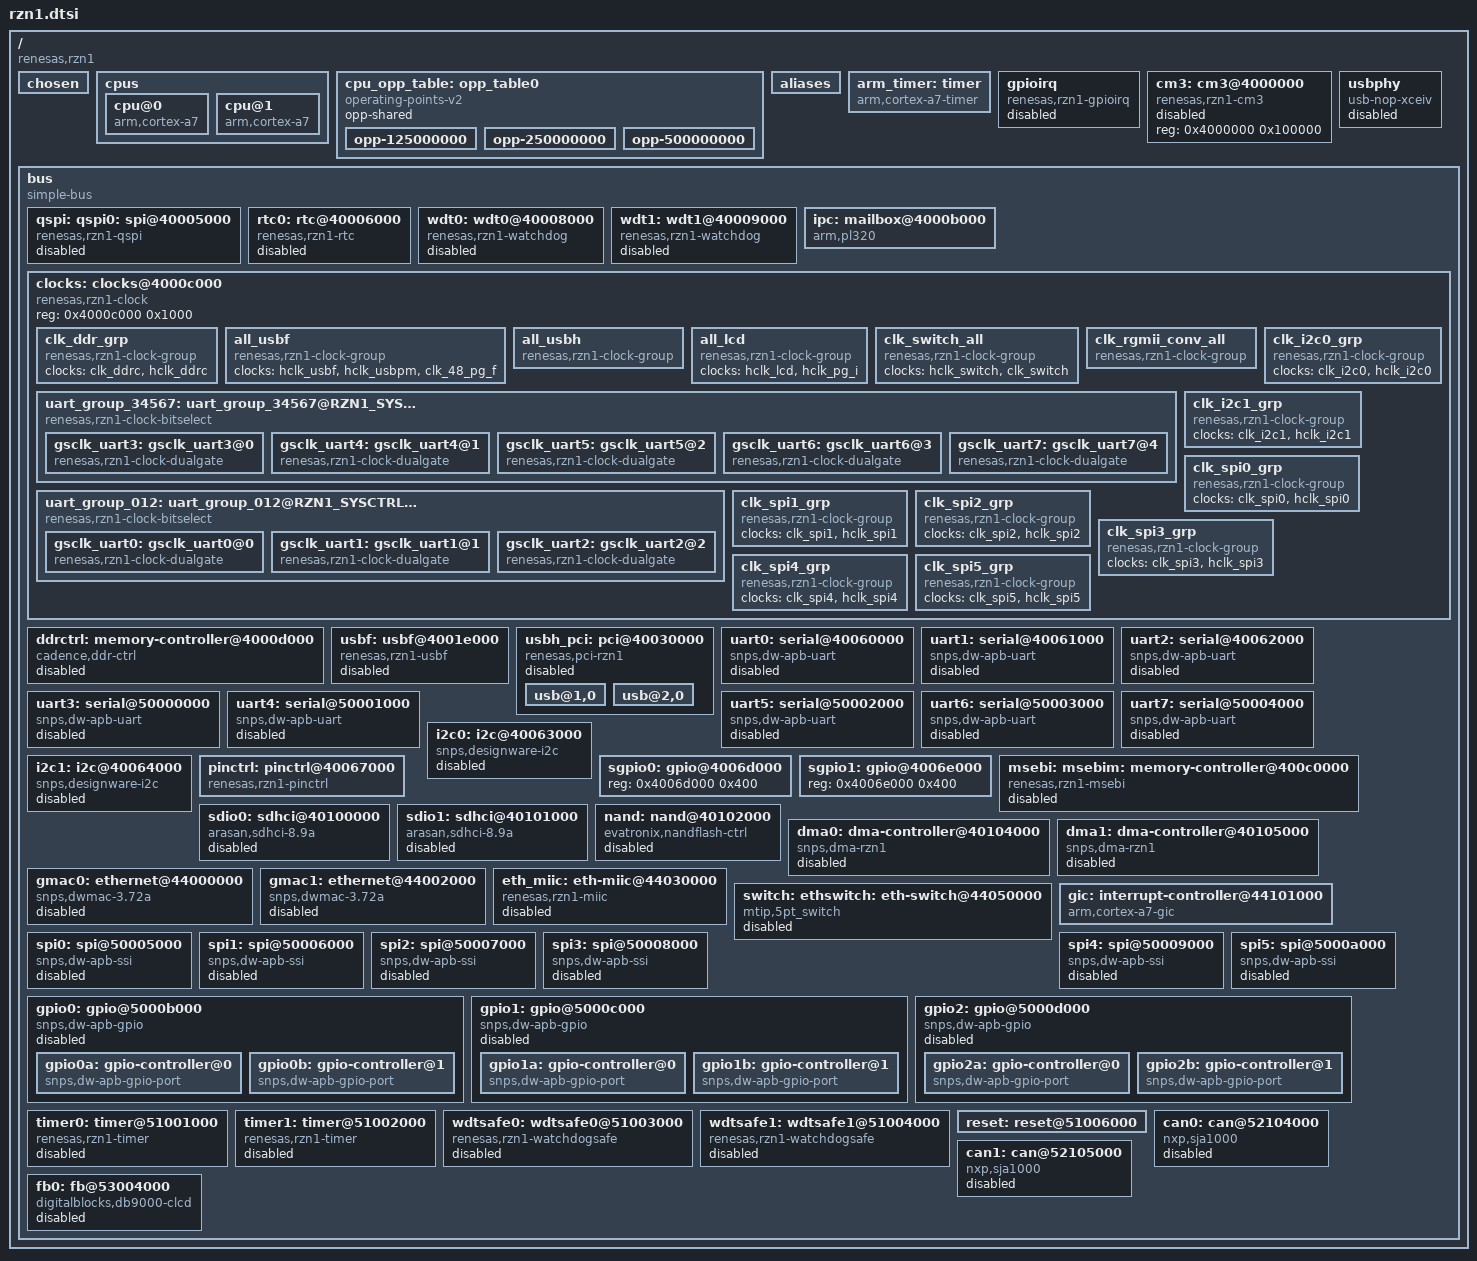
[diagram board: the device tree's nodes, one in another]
/*
 * Device Tree Source for the Renesas RZ/N1 SoC
 *
 * Copyright (C) 2016 Renesas Electronics Europe Ltd
 *
 * This file is licensed under the terms of the GNU General Public License
 * version 2.  This program is licensed "as is" without any warranty of any
 * kind, whether express or implied.
 */

#include <dt-bindings/interrupt-controller/arm-gic.h>
#include <dt-bindings/gpio/gpio.h>
#include <dt-bindings/interrupt-controller/rzn1-irq.h>
#include <dt-bindings/soc/rzn1-memory-map.h>
#include <dt-bindings/soc/rzn1-sysctrl.h>
#include <dt-bindings/pinctrl/pinctrl-rzn1.h>
#include <dt-bindings/clock/rzn1-clocks.h>

#include "skeleton.dtsi"

/ {
	compatible = "renesas,rzn1";
	#address-cells = <1>;
	#size-cells = <1>;

	chosen {
		/* These nodes are specific to the rzn1, and are CAN by the
		 * bootloader. They are optional
		   rzn1,bootaddr = <0xxxxxxxxx>  -- this property is set
		        by the bootloader when it starts in NONSEC mode, this
		        property will contain the address that the second CA7
		        core is 'parked' at, and where it is looking for the
		        boot address code the kernel will pass to it to start it.
		        This property should not be set manually.
		   rzn1,h2mode   -- this bool property, if present, will force
		        the kernel to configure the USB subsystem in 'host' mode,
		        this mode will prevent the usbf 'device' driver to start.
		        This property can be set by the bootloader in case there
		        is a GPIO for this configutation, otherwise, it can also
		        be set manually in the device tree to force a config.
		 */
	};
	cpus {
		#address-cells = <1>;
		#size-cells = <0>;

		cpu@0 {
			device_type = "cpu";
			compatible = "arm,cortex-a7";
			reg = <0>;
			clocks = <&clk_a7mp>;
			operating-points-v2 = <&cpu_opp_table>;
		};
		cpu@1 {
			device_type = "cpu";
			compatible = "arm,cortex-a7";
			reg = <1>;
			clocks = <&clk_a7mp>;
			operating-points-v2 = <&cpu_opp_table>;
		};
	};

	cpu_opp_table: opp_table0 {
		compatible = "operating-points-v2";
		opp-shared;

		opp-125000000 {
			opp-hz = /bits/ 64 <125000000>;
			/* ~35 clocks cycles at 125mhz */
			clock-latency-ns = <300>;
		};
		opp-250000000 {
			opp-hz = /bits/ 64 <250000000>;
			clock-latency-ns = <300>;
		};
		opp-500000000 {
			opp-hz = /bits/ 64 <500000000>;
			clock-latency-ns = <300>;
		};
	};

	aliases {
		serial0 = &uart0;
		ethernet0 = &gmac0;
		ethernet1 = &gmac1;
		spi0 = &qspi0;
		i2c0 = &i2c0;
		i2c1 = &i2c1;
	};

	arm_timer: timer {
		compatible = "arm,cortex-a7-timer",
			     "arm,armv7-timer";
		interrupt-parent = <&gic>;
		arm,cpu-registers-not-fw-configured;
		always-on;
		interrupts =
			<GIC_PPI 13 (GIC_CPU_MASK_SIMPLE(2) | IRQ_TYPE_LEVEL_LOW)>,
			<GIC_PPI 14 (GIC_CPU_MASK_SIMPLE(2) | IRQ_TYPE_LEVEL_LOW)>,
			<GIC_PPI 11 (GIC_CPU_MASK_SIMPLE(2) | IRQ_TYPE_LEVEL_LOW)>,
			<GIC_PPI 10 (GIC_CPU_MASK_SIMPLE(2) | IRQ_TYPE_LEVEL_LOW)>;
	};

	gpioirq: gpioirq {
		compatible = "renesas,rzn1-gpioirq";
		status = "disabled";
		interrupt-parent = <&gic>;
		interrupts =
			<GIC_SPI 103 IRQ_TYPE_LEVEL_HIGH>,
			<GIC_SPI 104 IRQ_TYPE_LEVEL_HIGH>,
			<GIC_SPI 105 IRQ_TYPE_LEVEL_HIGH>,
			<GIC_SPI 106 IRQ_TYPE_LEVEL_HIGH>,
			<GIC_SPI 107 IRQ_TYPE_LEVEL_HIGH>,
			<GIC_SPI 108 IRQ_TYPE_LEVEL_HIGH>,
			<GIC_SPI 109 IRQ_TYPE_LEVEL_HIGH>,
			<GIC_SPI 110 IRQ_TYPE_LEVEL_HIGH>;
		interrupt-controller;
		#interrupt-cells = <1>;
	};

	cm3: cm3@4000000 {
		compatible = "renesas,rzn1-cm3";
		#address-cells = <1>;
		#size-cells = <0>;
		status = "disabled";
		reg = <0x4000000 0x100000>;
		/* Optional, load and run a CM3 firmware at boot time */
		/* firmware-name = "cm3-freertos.bin"; */
	};

	usbphy: usbphy {
		#phy-cells = <0>;
		compatible = "usb-nop-xceiv";
		status = "disabled";
	};

	bus {
		compatible = "simple-bus";
		#address-cells = <1>;
		#size-cells = <1>;
		interrupt-parent = <&gic>;
		ranges;
		u-boot,dm-pre-reloc;

		qspi: qspi0: spi@40005000 {
			compatible = "renesas,rzn1-qspi";
			#address-cells = <1>;
			#size-cells = <0>;
			reg = <0x40005000 0x1000
				0x10000000 0x10000000>;
			reg-names = "qspi", "qspi-mapping";
			interrupts = <GIC_SPI 64 IRQ_TYPE_LEVEL_HIGH>;
			clocks = <&hclk_qspi0>, <&clk_qspi0>;
			clock-names = "flexway", "pclk";
			status = "disabled";
		};

		rtc0: rtc@40006000 {
			#address-cells = <1>;
			compatible = "renesas,rzn1-rtc";
			reg = <0x40006000 0x1000>;
			clock-names = "axi";
			clocks = <&hclk_rtc>;
			interrupt-names = "alarm", "intr", "1hz";
			interrupts =
				<GIC_SPI 66 IRQ_TYPE_EDGE_RISING>,
				<GIC_SPI 67 IRQ_TYPE_EDGE_RISING>,
				<GIC_SPI 68 IRQ_TYPE_EDGE_RISING>;
			status = "disabled";
		};

		wdt0: wdt0@40008000 {
			compatible = "renesas,rzn1-watchdog";
			reg = <0x40008000 0x1000>;
			interrupts = <GIC_SPI 73 IRQ_TYPE_EDGE_RISING>;
			clocks = <&clk_ref_sync_d8>;
			status = "disabled";
		};

		wdt1: wdt1@40009000 {
			compatible = "renesas,rzn1-watchdog";
			reg = <0x40009000 0x1000>;
			interrupts = <GIC_SPI 74 IRQ_TYPE_EDGE_RISING>;
			clocks = <&clk_ref_sync_d8>;
			status = "disabled";
		};

		ipc: mailbox@4000b000 {
		    compatible = "arm,pl320", "arm,primecell";
		    reg = <0x4000b000 0x1000>;
		    interrupts = <GIC_SPI 60 IRQ_TYPE_LEVEL_HIGH>;
		    clocks = <&clk_fw>;
		    clock-names = "apb_pclk";
		};

		clocks: clocks@4000c000 {
			compatible = "renesas,rzn1-clock";
			reg = <0x4000c000 0x1000>;
			#address-cells = <1>;
			#size-cells = <0>;
			status = "okay";

			/* Most of the clock definition is declared in the
			 * autogenerated file rzn1-clocks.dtsi
			 * Here we find the 'exceptions' - mostly grouping clocks
			 * together to attach to drivers */

			clk_ddr_grp: clk_ddr_grp {
				#clock-cells = <0>;
				compatible = "renesas,rzn1-clock-group";
				clocks = <&clk_ddrc &hclk_ddrc>;
			};
			all_usbf: all_usbf {
				#clock-cells = <0>;
				compatible = "renesas,rzn1-clock-group";
				clocks = <&hclk_usbf &hclk_usbpm &clk_48_pg_f>;
			};
			/* USB Host Needs the USB Device clocks(!) since the EPCTR
			 * register is in the USBF register map, and that register is
			 * needed to start the PLL */
			all_usbh: all_usbh {
				#clock-cells = <0>;
				compatible = "renesas,rzn1-clock-group";
				clocks = <&hclk_usbh &hclk_usbpm &clk_pci_usb &all_usbf>;
			};
			all_lcd: all_lcd {
				#clock-cells = <0>;
				compatible = "renesas,rzn1-clock-group";
				clocks = <&hclk_lcd &hclk_pg_i>;
			};
			clk_switch_all: clk_switch_all {
				#clock-cells = <0>;
				compatible = "renesas,rzn1-clock-group";
				clocks = <&hclk_switch &clk_switch>;
			};
			clk_rgmii_conv_all: clk_rgmii_conv_all {
				#clock-cells = <0>;
				compatible = "renesas,rzn1-clock-group";
				clocks = <&clk_mii_ref &clk_rmii_ref &clk_rgmii_ref &hclk_switch_rg>;
			};
			uart_group_34567: uart_group_34567@RZN1_SYSCTRL_REG_PWRCTRL_PG1_PR2 {
				#clock-cells = <0>;
				#address-cells = <1>;
				#size-cells = <0>;

				compatible = "renesas,rzn1-clock-bitselect";
				/* Bit 24 is UARTCLKSEL */
				reg = <RZN1_SYSCTRL_REG_PWRCTRL_PG1_PR2>;
				renesas,rzn1-sel-bit = <24>;

				/* If that bit is zero, use first parent, else,
				 * use second parent */
				clocks = <&div_p2_pg>, <&clk_48>;

				/* First group are gates for when selector bit
				 * is zero, second group is the gates to use when
				 * bit is 'one' */
				renesas,rzn1-gates =
				      <RZN1_CLK_UART3_ID RZN1_CLK_UART4_ID
					RZN1_CLK_UART5_ID RZN1_CLK_UART6_ID
					RZN1_CLK_UART7_ID>,
				      <RZN1_CLK_USBUART3_ID RZN1_CLK_USBUART4_ID
					RZN1_CLK_USBUART5_ID RZN1_CLK_USBUART6_ID
					RZN1_CLK_USBUART7_ID>;

				gsclk_uart3: gsclk_uart3@0 {
					#clock-cells = <0>;
					compatible = "renesas,rzn1-clock-dualgate";
					clocks = <&uart_group_34567>;
					reg = <0>;
				 };
				gsclk_uart4: gsclk_uart4@1 {
					#clock-cells = <0>;
					compatible = "renesas,rzn1-clock-dualgate";
					clocks = <&uart_group_34567>;
					reg = <1>;
				 };
				gsclk_uart5: gsclk_uart5@2 {
					#clock-cells = <0>;
					compatible = "renesas,rzn1-clock-dualgate";
					clocks = <&uart_group_34567>;
					reg = <2>;
				 };
				gsclk_uart6: gsclk_uart6@3 {
					#clock-cells = <0>;
					compatible = "renesas,rzn1-clock-dualgate";
					clocks = <&uart_group_34567>;
					reg = <3>;
				 };
				gsclk_uart7: gsclk_uart7@4 {
					#clock-cells = <0>;
					compatible = "renesas,rzn1-clock-dualgate";
					clocks = <&uart_group_34567>;
					reg = <4>;
				 };
			 };
			 uart_group_012: uart_group_012@RZN1_SYSCTRL_REG_PWRCTRL_PG0_0 {
				#clock-cells = <0>;
				#address-cells = <1>;
				#size-cells = <0>;

				compatible = "renesas,rzn1-clock-bitselect";
				/* Bit 24 is UARTCLKSEL */
				reg = <RZN1_SYSCTRL_REG_PWRCTRL_PG0_0>;
				renesas,rzn1-sel-bit = <30>;

				/* If that bit is zero, use first parent, else,
				 * use second parent */
				clocks = <&div_uart>, <&clk_48>;

				/* First group are gates for when selector bit
				 * is zero, second group is the gates to use when
				 * bit is 'one' */
				renesas,rzn1-gates =
				      <RZN1_CLK_UART0_ID RZN1_CLK_UART1_ID
					RZN1_CLK_UART2_ID>,
				      <RZN1_CLK_USBUART0_ID RZN1_CLK_USBUART1_ID
					RZN1_CLK_USBUART2_ID>;
				gsclk_uart0: gsclk_uart0@0 {
					#clock-cells = <0>;
					compatible = "renesas,rzn1-clock-dualgate";
					clocks = <&uart_group_012>;
					reg = <0>;
				 };
				gsclk_uart1: gsclk_uart1@1 {
					#clock-cells = <0>;
					compatible = "renesas,rzn1-clock-dualgate";
					clocks = <&uart_group_012>;
					reg = <1>;
				 };
				gsclk_uart2: gsclk_uart2@2 {
					#clock-cells = <0>;
					compatible = "renesas,rzn1-clock-dualgate";
					clocks = <&uart_group_012>;
					reg = <2>;
				};
			};
			clk_i2c0_grp: clk_i2c0_grp {
				#clock-cells = <0>;
				compatible = "renesas,rzn1-clock-group";
				clocks = <&clk_i2c0 &hclk_i2c0>;
			};
			clk_i2c1_grp: clk_i2c1_grp {
				#clock-cells = <0>;
				compatible = "renesas,rzn1-clock-group";
				clocks = <&clk_i2c1 &hclk_i2c1>;
			};
			clk_spi0_grp: clk_spi0_grp {
				#clock-cells = <0>;
				compatible = "renesas,rzn1-clock-group";
				clocks = <&clk_spi0>, <&hclk_spi0>;
			};
			clk_spi1_grp: clk_spi1_grp {
				#clock-cells = <0>;
				compatible = "renesas,rzn1-clock-group";
				clocks = <&clk_spi1>, <&hclk_spi1>;
			};
			clk_spi2_grp: clk_spi2_grp {
				#clock-cells = <0>;
				compatible = "renesas,rzn1-clock-group";
				clocks = <&clk_spi2>, <&hclk_spi2>;
			};
			clk_spi3_grp: clk_spi3_grp {
				#clock-cells = <0>;
				compatible = "renesas,rzn1-clock-group";
				clocks = <&clk_spi3>, <&hclk_spi3>;
			};
			clk_spi4_grp: clk_spi4_grp {
				#clock-cells = <0>;
				compatible = "renesas,rzn1-clock-group";
				clocks = <&clk_spi4>, <&hclk_spi4>;
			};
			clk_spi5_grp: clk_spi5_grp {
				#clock-cells = <0>;
				compatible = "renesas,rzn1-clock-group";
				clocks = <&clk_spi5>, <&hclk_spi5>;
			};
		};

		ddrctrl: memory-controller@4000d000 {
			compatible = "cadence,ddr-ctrl";
			reg = <0x4000d000 0x1000>;
			interrupts = <GIC_SPI 76 IRQ_TYPE_LEVEL_HIGH>;
			clocks = <&clk_ddr_grp>;
			status = "disabled";
		};

		usbf: usbf@4001e000 {
			compatible = "renesas,rzn1-usbf";
			reg = <0x4001e000 0x2000>;
			interrupts =
				<GIC_SPI 77 IRQ_TYPE_LEVEL_HIGH>,
				<GIC_SPI 78 IRQ_TYPE_LEVEL_HIGH>;
			clock-names = "axi";
			clocks = <&all_usbf>;

			renesas,sram-size = <5024>; /* 32 bits words */
			/* Allow 4 x 512 byte packets per endpoint to support MTU of 1500.
			Due to protocol overheads, 3 x 512 byte packets is not enough. */
			renesas,sram-conf,g_ether = <4 2 0>;
			renesas,sram-conf,g_mass_storage = <8 8 0 0 0 0>;
			status = "disabled";
		};

		usbh_pci: pci@40030000 {
			compatible = "renesas,pci-rzn1";
			device_type = "pci";
			clock-names = "axi";
			clocks = <&all_usbh>;
			reg = <0x40030000 0xc00>,
			      <0x40020000 0x1100>;
			interrupts = <GIC_SPI 79 IRQ_TYPE_LEVEL_HIGH>;
			status = "disabled";

			bus-range = <0 0>;
			#address-cells = <3>;
			#size-cells = <2>;
			#interrupt-cells = <1>;
			ranges = <0x02000000 0 0x40020000 0x20000 0 0x00010000>;
			/* Should map all possible DDR as inbound ranges, but
			   the IP only supports a 256MB, 512MB, or 1GB window */
			/* flags, PCI addr (64-bit), CPU addr, PCI size (64-bit) */
			dma-ranges = <0x42000000 0 0x80000000 0x80000000 0 0x40000000>;
			interrupt-map-mask = <0xff00 0 0 0x7>;
			interrupt-map = <0x0000 0 0 1 &gic GIC_SPI 79 IRQ_TYPE_LEVEL_HIGH
					 0x0800 0 0 1 &gic GIC_SPI 79 IRQ_TYPE_LEVEL_HIGH
					 0x1000 0 0 2 &gic GIC_SPI 79 IRQ_TYPE_LEVEL_HIGH>;

			usb@1,0 {
				reg = <0x800 0 0 0 0>;
				phys = <&usbphy 0>;
				phy-names = "usb";
			};

			usb@2,0 {
				reg = <0x1000 0 0 0 0>;
				phys = <&usbphy 0>;
				phy-names = "usb";
			};
		};

		uart0: serial@40060000 {
			compatible = "snps,dw-apb-uart";
			snps,rzn1-uart;
			reg = <0x40060000 0x400>;
			interrupts = <GIC_SPI 6 IRQ_TYPE_LEVEL_HIGH>;
			reg-shift = <2>;
			reg-io-width = <4>;
			cpr-value = <0x00010f32>;
			clocks = <&gsclk_uart0 &hclk_uart0>;
			clock-names = "baudclk", "apb_pclk";
			status = "disabled";
		};

		uart1: serial@40061000 {
			compatible = "snps,dw-apb-uart";
			snps,rzn1-uart;
			reg = <0x40061000 0x400>;
			interrupts = <GIC_SPI 7 IRQ_TYPE_LEVEL_HIGH>;
			reg-shift = <2>;
			reg-io-width = <4>;
			cpr-value = <0x00010f32>;
			clocks = <&gsclk_uart1 &hclk_uart1>;
			clock-names = "baudclk", "apb_pclk";
			status = "disabled";
		};

		uart2: serial@40062000 {
			compatible = "snps,dw-apb-uart";
			snps,rzn1-uart;
			reg = <0x40062000 0x400>;
			interrupts = <GIC_SPI 8 IRQ_TYPE_LEVEL_HIGH>;
			reg-shift = <2>;
			reg-io-width = <4>;
			cpr-value = <0x00010f32>;
			clocks = <&gsclk_uart2 &hclk_uart2>;
			clock-names = "baudclk", "apb_pclk";
			status = "disabled";
		};

		uart3: serial@50000000 {
			compatible = "snps,dw-apb-uart";
			snps,rzn1-uart;
			reg = <0x50000000 0x400>;
			interrupts = <GIC_SPI 86 IRQ_TYPE_LEVEL_HIGH>;
			reg-shift = <2>;
			reg-io-width = <4>;
			cpr-value = <0x00012f32>;
			clocks = <&gsclk_uart3 &hclk_uart3>;
			clock-names = "baudclk", "apb_pclk";
			status = "disabled";
		};

		uart4: serial@50001000 {
			compatible = "snps,dw-apb-uart";
			snps,rzn1-uart;
			reg = <0x50001000 0x400>;
			interrupts = <GIC_SPI 87 IRQ_TYPE_LEVEL_HIGH>;
			reg-shift = <2>;
			reg-io-width = <4>;
			cpr-value = <0x00012f32>;
			clocks = <&gsclk_uart4 &hclk_uart4>;
			clock-names = "baudclk", "apb_pclk";
			status = "disabled";
		};

		uart5: serial@50002000 {
			compatible = "snps,dw-apb-uart";
			snps,rzn1-uart;
			reg = <0x50002000 0x400>;
			interrupts = <GIC_SPI 88 IRQ_TYPE_LEVEL_HIGH>;
			reg-shift = <2>;
			reg-io-width = <4>;
			cpr-value = <0x00012f32>;
			clocks = <&gsclk_uart5 &hclk_uart5>;
			clock-names = "baudclk", "apb_pclk";
			status = "disabled";
		};

		uart6: serial@50003000 {
			compatible = "snps,dw-apb-uart";
			snps,rzn1-uart;
			reg = <0x50003000 0x400>;
			interrupts = <GIC_SPI 89 IRQ_TYPE_LEVEL_HIGH>;
			reg-shift = <2>;
			reg-io-width = <4>;
			cpr-value = <0x00012f32>;
			clocks = <&gsclk_uart6 &hclk_uart6>;
			clock-names = "baudclk", "apb_pclk";
			status = "disabled";
		};

		uart7: serial@50004000 {
			compatible = "snps,dw-apb-uart";
			snps,rzn1-uart;
			reg = <0x50004000 0x400>;
			interrupts = <GIC_SPI 90 IRQ_TYPE_LEVEL_HIGH>;
			reg-shift = <2>;
			reg-io-width = <4>;
			cpr-value = <0x00012f32>;
			clocks = <&gsclk_uart7 &hclk_uart7>;
			clock-names = "baudclk", "apb_pclk";
			status = "disabled";
		};

		i2c0: i2c@40063000 {
			#address-cells = <1>;
			#size-cells = <0>;
			compatible = "snps,designware-i2c";
			reg = <0x40063000 0x100>;
			interrupts = <GIC_SPI 1 IRQ_TYPE_LEVEL_HIGH>;
			clock-names = "pclk";
			clocks = <&clk_i2c0_grp>;
			clock-frequency = <100000>;
			status = "disabled";
		};

		i2c1: i2c@40064000 {
			#address-cells = <1>;
			#size-cells = <0>;
			compatible = "snps,designware-i2c";
			reg = <0x40064000 0x100>;
			interrupts = <GIC_SPI 2 IRQ_TYPE_LEVEL_HIGH>;
			clock-names = "pclk";
			clocks = <&clk_i2c1_grp>;
			clock-frequency = <100000>;
			status = "disabled";
		};

		pinctrl: pinctrl@40067000 {
			compatible = "renesas,rzn1-pinctrl";
			reg = <0x40067000 0x1000>,
				<0x51000000 0x800>;
			#address-cells = <1>;
			#size-cells = <0>;
			clocks = <&hclk_pinconfig>;
			clock-names = "bus";
			status = "okay";
		};

		sgpio0: gpio@4006d000 {
			reg = <0x4006d000 0x400>;
		};

		sgpio1: gpio@4006e000 {
			reg = <0x4006e000 0x400>;
		};

		msebi: msebim: memory-controller@400c0000 {
			compatible = "renesas,rzn1-msebi";
			#address-cells = <2>;
			#size-cells = <1>;
			reg = <0x400c0000 0x2000>;
			interrupts = <GIC_SPI 62 IRQ_TYPE_LEVEL_HIGH>;
			clocks = <&hclk_msebi_m>;
			status = "disabled";
		};

		sdio0: sdhci@40100000 {
			compatible = "arasan,sdhci-8.9a";
			reg = <0x40100000 0x1000>;
			interrupts = <GIC_SPI 69 IRQ_TYPE_LEVEL_HIGH>,
				     <GIC_SPI 70 IRQ_TYPE_LEVEL_HIGH>;
			clock-names = "clk_xin", "clk_ahb";
			clocks = <&clk_sdio0>, <&hclk_sdio0>;
			no-1-8-v;
			status = "disabled";
		};

		sdio1: sdhci@40101000 {
			compatible = "arasan,sdhci-8.9a";
			reg = <0x40101000 0x1000>;
			interrupts = <GIC_SPI 71 IRQ_TYPE_LEVEL_HIGH>,
				     <GIC_SPI 72 IRQ_TYPE_LEVEL_HIGH>;
			clock-names = "clk_xin", "clk_ahb";
			clocks = <&clk_sdio1>, <&hclk_sdio1>;
			no-1-8-v;
			status = "disabled";
		};

		nand: nand@40102000 {
			compatible = "evatronix,nandflash-ctrl";
			reg = <0x40102000 0x2000>;
			interrupts = <GIC_SPI 58 IRQ_TYPE_LEVEL_HIGH>;
			clocks = <&hclk_nand>, <&clk_nand>;
			clock-names = "clka", "clkb";
			#address-cells		= <1>;
			#size-cells		= <1>;
			status = "disabled";
		};

		dma0: dma-controller@40104000 {
			compatible = "snps,dma-rzn1";
			reg = <0x40104000 0x1000>;
			interrupts = <GIC_SPI 56 IRQ_TYPE_LEVEL_HIGH>;
			clock-names = "hclk";
			clocks = <&hclk_dma0>;
			dma-channels = <8>;
			dma-requests = <16>;
			dma-masters = <1>;
			#dma-cells = <3>;
			block_size = <0xfff>;
			data_width = <3>;
			status = "disabled";
		};

		dma1: dma-controller@40105000 {
			compatible = "snps,dma-rzn1";
			reg = <0x40105000 0x1000>;
			interrupts = <GIC_SPI 57 IRQ_TYPE_LEVEL_HIGH>;
			clock-names = "hclk";
			clocks = <&hclk_dma1>;
			dma-channels = <8>;
			dma-requests = <16>;
			dma-masters = <1>;
			#dma-cells = <3>;
			block_size = <0xfff>;
			data_width = <3>;
			status = "disabled";
		};

		gmac0: ethernet@44000000 {
			compatible = "snps,dwmac-3.72a", "snps,dwmac";
			reg = <0x44000000 0x2000>;
			interrupt-parent = <&gic>;
			interrupts = <GIC_SPI 34 IRQ_TYPE_LEVEL_HIGH>,
				     <GIC_SPI 35 IRQ_TYPE_LEVEL_HIGH>,
				     <GIC_SPI 36 IRQ_TYPE_LEVEL_HIGH>;
			interrupt-names = "macirq", "eth_lpi", "eth_wake_irq";
			clock-names = "stmmaceth";
			clocks = <&hclk_gmac0>;
			status = "disabled";
		};

		gmac1: ethernet@44002000 {
			compatible = "snps,dwmac-3.72a", "snps,dwmac";
			reg = <0x44002000 0x2000>;
			interrupt-parent = <&gic>;
			interrupts = <GIC_SPI 37 IRQ_TYPE_LEVEL_HIGH>,
				     <GIC_SPI 38 IRQ_TYPE_LEVEL_HIGH>,
				     <GIC_SPI 39 IRQ_TYPE_LEVEL_HIGH>;
			interrupt-names = "macirq", "eth_lpi", "eth_wake_irq";
			clock-names = "stmmaceth";
			clocks = <&hclk_gmac1>;
			status = "disabled";
		};

		eth_miic: eth-miic@44030000 {
			compatible = "renesas,rzn1-miic";
			#address-cells = <1>;
			reg = <0x44030000 0x10000>;
			status = "disabled";
			clocks = <&clk_rgmii_conv_all>;
		};

		switch: ethswitch: eth-switch@44050000 {
			compatible = "mtip,5pt_switch";
			#address-cells = <1>;
			#size-cells = <0>;
			reg = <0x44050000 0x10000>;
			clock-names = "fck";
			clocks = <&clk_switch_all>;
			status = "disabled";
		};

		gic: interrupt-controller@44101000 {
			compatible = "arm,cortex-a7-gic";
			reg = <0x44101000 0x1000>,	/* Distributer */
			      <0x44102000 0x1000>,	/* CPU interface */
			      <0x44104000 0x2000>,	/* Virt interface control */
			      <0x44106000 0x2000>;	/* Virt CPU interface */
			interrupt-controller;
			#interrupt-cells = <3>;
			interrupts =
				<GIC_PPI 9 (GIC_CPU_MASK_SIMPLE(2) |
					IRQ_TYPE_LEVEL_HIGH)>;
		};

		/*
		 * SPI 0-3 are Master; 4-5 are Slave. 4-16 bits data width
		 * dw_apb-ssi is configured with 16*16 bits FIFO in both
		 * directions.
		 * 4 Chipselects for the master interfaces, 1 for slaves
		 */
		spi0: spi@50005000 {
			compatible = "snps,dw-apb-ssi";
			reg = <0x50005000 0x400>;
			interrupts = <GIC_SPI 80 IRQ_TYPE_LEVEL_HIGH>;
			clock-names = "pclk";
			clocks = <&clk_spi0_grp>;
			#address-cells = <1>;
			#size-cells = <0>;
			spi-max-frequency = <12500000>;
			num-cs = <4>;
			status = "disabled";
		};

		spi1: spi@50006000 {
			compatible = "snps,dw-apb-ssi";
			reg = <0x50006000 0x400>;
			interrupts = <GIC_SPI 81 IRQ_TYPE_LEVEL_HIGH>;
			clock-names = "pclk";
			clocks = <&clk_spi1_grp>;
			#address-cells = <1>;
			#size-cells = <0>;
			spi-max-frequency = <12500000>;
			num-cs = <4>;
			status = "disabled";
		};

		spi2: spi@50007000 {
			compatible = "snps,dw-apb-ssi";
			reg = <0x50007000 0x400>;
			interrupts = <GIC_SPI 82 IRQ_TYPE_LEVEL_HIGH>;
			clock-names = "pclk";
			clocks = <&clk_spi2_grp>;
			#address-cells = <1>;
			#size-cells = <0>;
			spi-max-frequency = <12500000>;
			num-cs = <4>;
			status = "disabled";
		};

		spi3: spi@50008000 {
			compatible = "snps,dw-apb-ssi";
			reg = <0x50008000 0x400>;
			interrupts = <GIC_SPI 83 IRQ_TYPE_LEVEL_HIGH>;
			clock-names = "pclk";
			clocks = <&clk_spi3_grp>;
			#address-cells = <1>;
			#size-cells = <0>;
			spi-max-frequency = <12500000>;
			num-cs = <4>;
			status = "disabled";
		};

		spi4: spi@50009000 {
			compatible = "snps,dw-apb-ssi";
			reg = <0x50009000 0x400>;
			interrupts = <GIC_SPI 84 IRQ_TYPE_LEVEL_HIGH>;
			clock-names = "pclk";
			clocks = <&clk_spi4_grp>;
			#address-cells = <1>;
			#size-cells = <0>;
			spi-max-frequency = <12500000>;
			num-cs = <1>; /* Slave interface */
			status = "disabled";
		};

		spi5: spi@5000a000 {
			compatible = "snps,dw-apb-ssi";
			reg = <0x5000a000 0x400>;
			interrupts = <GIC_SPI 85 IRQ_TYPE_LEVEL_HIGH>;
			clock-names = "pclk";
			clocks = <&clk_spi5_grp>;
			#address-cells = <1>;
			#size-cells = <0>;
			spi-max-frequency = <12500000>;
			num-cs = <1>; /* Slave interface */
			status = "disabled";
		};

		/*
		 * The GPIO mapping to the corresponding pins is complicted,
		 * see the hardware documentation for details.
		 */
		gpio0: gpio@5000b000 {
			compatible = "snps,dw-apb-gpio";
			reg = <0x5000b000 0x80>;
			#address-cells = <1>;
			#size-cells = <0>;
			clocks = <&hclk_gpio0>;
			status = "disabled";

			gpio0a: gpio-controller@0 {
				compatible = "snps,dw-apb-gpio-port";
				bank-name = "gpio0a";
				gpio-controller;
				#gpio-cells = <2>;
				snps,nr-gpios = <32>;
				reg = <0>;

				/*
				 * There are 32 irqs going from this gpio block
				 * to the gpio irq mux block, hence the large
				 * list of interrupts.
				 */
				interrupt-parent = <&gpioirq>;
				interrupts =   < 0  1  2  3  4  5  6  7
						 8  9 10 11 12 13 14 15
						16 17 18 19 20 21 22 23
						24 25 26 27 28 29 30 31 >;
				interrupt-controller;
				#interrupt-cells = <2>;
			};
			gpio0b: gpio-controller@1 {
				compatible = "snps,dw-apb-gpio-port";
				bank-name = "gpio0b";
				gpio-controller;
				#gpio-cells = <2>;
				snps,nr-gpios = <32>;
				reg = <1>;
			};
		};

		gpio1: gpio@5000c000 {
			compatible = "snps,dw-apb-gpio";
			reg = <0x5000c000 0x80>;
			#address-cells = <1>;
			#size-cells = <0>;
			clocks = <&hclk_gpio1>;
			status = "disabled";

			/* GPIO1a[0..4] corresponds to pins 45..49 */
			/* GPIO1a[5..31] corresponds to pins 71..121 */
			gpio1a: gpio-controller@0 {
				compatible = "snps,dw-apb-gpio-port";
				bank-name = "gpio1a";
				gpio-controller;
				#gpio-cells = <2>;
				snps,nr-gpios = <32>;
				reg = <0>;

				/*
				 * There are 32 irqs going from this gpio block
				 * to the gpio irq mux block, hence the large
				 * list of interrupts.
				 */
				interrupt-parent = <&gpioirq>;
				interrupts =  < 32 33 34 35 36 37 38 39
						40 41 42 43 44 45 46 47
						48 49 50 51 52 53 54 55
						56 57 58 59 60 61 62 63 >;
				interrupt-controller;
				#interrupt-cells = <2>;
			};
			/* GPIO1b[0..1] corresponds to pins 31..32 */
			/* GPIO1b[2..4] corresponds to pins 35..37 */
			/* GPIO1b[5..25] corresponds to pins 50..70 */
			/* GPIO1b[26..31] corresponds to pins 150..155 */
			gpio1b: gpio-controller@1 {
				compatible = "snps,dw-apb-gpio-port";
				bank-name = "gpio1b";
				gpio-controller;
				#gpio-cells = <2>;
				snps,nr-gpios = <32>;
				reg = <1>;
			};
		};

		gpio2: gpio@5000d000 {
			compatible = "snps,dw-apb-gpio";
			reg = <0x5000d000 0x80>;
			#address-cells = <1>;
			#size-cells = <0>;
			clocks = <&hclk_gpio2>;
			status = "disabled";

			/* GPIO2a[0..27] corresponds to pins 122..149 */
			/* GPIO2a[28..31] corresponds to pins 156..159 */
			gpio2a: gpio-controller@0 {
				compatible = "snps,dw-apb-gpio-port";
				bank-name = "gpio2a";
				gpio-controller;
				#gpio-cells = <2>;
				snps,nr-gpios = <32>;
				reg = <0>;

				/*
				 * There are 32 irqs going from this gpio block
				 * to the gpio irq mux block, hence the large
				 * list of interrupts.
				 */
				interrupt-parent = <&gpioirq>;
				interrupts =  < 64 65 66 67 68 69 70 71
						72 73 74 75 76 77 78 79
						80 81 82 83 84 85 86 87
						88 89 90 91 92 93 94 95 >;
				interrupt-controller;
				#interrupt-cells = <2>;
			};
			/* GPIO2b[0..9] corresponds to pins 160..169 */
			gpio2b: gpio-controller@1 {
				compatible = "snps,dw-apb-gpio-port";
				bank-name = "gpio2b";
				gpio-controller;
				#gpio-cells = <2>;
				snps,nr-gpios = <10>;
				reg = <1>;
			};
		};

		timer0: timer@51001000 {
			compatible = "renesas,rzn1-timer";
			reg = <0x51001000 0x400>;
			interrupts = <GIC_SPI 112 IRQ_TYPE_LEVEL_HIGH>,
				     <GIC_SPI 113 IRQ_TYPE_LEVEL_HIGH>,
				     <GIC_SPI 114 IRQ_TYPE_LEVEL_HIGH>,
				     <GIC_SPI 115 IRQ_TYPE_LEVEL_HIGH>,
				     <GIC_SPI 116 IRQ_TYPE_LEVEL_HIGH>,
				     <GIC_SPI 117 IRQ_TYPE_LEVEL_HIGH>,
				     <GIC_SPI 118 IRQ_TYPE_LEVEL_HIGH>,
				     <GIC_SPI 119 IRQ_TYPE_LEVEL_HIGH>;
			clocks = <&hclk_timer0>;
			status = "disabled";
		};

		timer1: timer@51002000 {
			compatible = "renesas,rzn1-timer";
			reg = <0x51002000 0x400>;
			renesas,timer-number = <1>;
			interrupts = <GIC_SPI 120 IRQ_TYPE_LEVEL_HIGH>,
				     <GIC_SPI 121 IRQ_TYPE_LEVEL_HIGH>,
				     <GIC_SPI 122 IRQ_TYPE_LEVEL_HIGH>,
				     <GIC_SPI 123 IRQ_TYPE_LEVEL_HIGH>,
				     <GIC_SPI 124 IRQ_TYPE_LEVEL_HIGH>,
				     <GIC_SPI 125 IRQ_TYPE_LEVEL_HIGH>,
				     <GIC_SPI 126 IRQ_TYPE_LEVEL_HIGH>,
				     <GIC_SPI 127 IRQ_TYPE_LEVEL_HIGH>;
			clocks = <&hclk_timer1>;
			status = "disabled";
		};

		wdtsafe0: wdtsafe0@51003000 {
			compatible = "renesas,rzn1-watchdogsafe";
			reg = <0x51003000 0x400>;
			interrupts = <GIC_SPI 100 IRQ_TYPE_LEVEL_HIGH>;
			clocks = <&hclk_pinconfig>;
			status = "disabled";
		};

		wdtsafe1: wdtsafe1@51004000 {
			compatible = "renesas,rzn1-watchdogsafe";
			reg = <0x51004000 0x400>;
			interrupts = <GIC_SPI 101 IRQ_TYPE_LEVEL_HIGH>;
			clocks = <&hclk_pinconfig>;
			status = "disabled";
		};

		reset: reset@51006000 {
			reg = <0x51006000 0x400>;
			clocks = <&hclk_pinconfig>;
		};

		can0: can@52104000 {
			compatible = "nxp,sja1000";
			reg = <0x52104000 0x800>;
			reg-io-width = <4>;
			interrupts = <GIC_SPI 95 IRQ_TYPE_LEVEL_HIGH>;
			nxp,no-cdr;
			nxp,no-loopback;
			clocks = <&hclk_can0>;
			status = "disabled";
		};

		can1: can@52105000 {
			compatible = "nxp,sja1000";
			reg = <0x52105000 0x800>;
			reg-io-width = <4>;
			interrupts = <GIC_SPI 96 IRQ_TYPE_LEVEL_HIGH>;
			nxp,no-cdr;
			nxp,no-loopback;
			clocks = <&hclk_can1>;
			status = "disabled";
		};

		fb0: fb@53004000 {
			compatible = "digitalblocks,db9000-clcd";
			reg = <0x53004000 0x1000>;
			interrupts = <GIC_SPI 97 IRQ_TYPE_LEVEL_HIGH>;
			clock-names = "pclk", "ahb";
			clocks = <&clk_slcd>, <&all_lcd>;
			status = "disabled";
		};
	};

};

#include "rzn1-clocks.dtsi"
